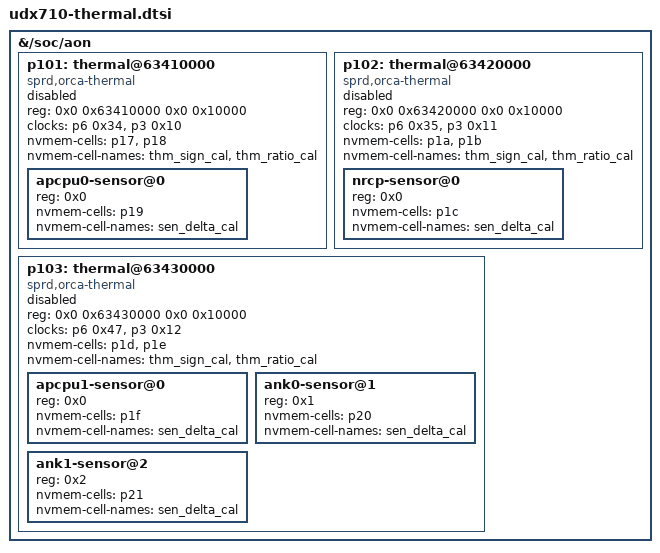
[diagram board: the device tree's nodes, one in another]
// SPDX-License-Identifier: GPL-2.0-only
/* UDX710 on-die thermal blocks and silicon calibration connections. */
&{/soc/aon} {
	p101: thermal@63410000 {
		compatible = "sprd,orca-thermal";
		reg = <0x0 0x63410000 0x0 0x10000>;
		clock-names = "enable", "functional";
		clocks = <&p6 0x34 &p3 0x10>;
		#thermal-sensor-cells = <0x1>;
		nvmem-cells = <&p17 &p18>;
		nvmem-cell-names = "thm_sign_cal", "thm_ratio_cal";
		phandle = <0x101>;
		#address-cells = <0x1>;
		#size-cells = <0x0>;
		status = "disabled";
		apcpu0-sensor@0 {
			reg = <0x0>;
			nvmem-cells = <&p19>;
			nvmem-cell-names = "sen_delta_cal";
		};
	};

	p102: thermal@63420000 {
		compatible = "sprd,orca-thermal";
		reg = <0x0 0x63420000 0x0 0x10000>;
		clock-names = "enable", "functional";
		clocks = <&p6 0x35 &p3 0x11>;
		#thermal-sensor-cells = <0x1>;
		nvmem-cells = <&p1a &p1b>;
		nvmem-cell-names = "thm_sign_cal", "thm_ratio_cal";
		phandle = <0x102>;
		#address-cells = <0x1>;
		#size-cells = <0x0>;
		status = "disabled";
		nrcp-sensor@0 {
			reg = <0x0>;
			nvmem-cells = <&p1c>;
			nvmem-cell-names = "sen_delta_cal";
		};
	};

	p103: thermal@63430000 {
		compatible = "sprd,orca-thermal";
		reg = <0x0 0x63430000 0x0 0x10000>;
		clock-names = "enable", "functional";
		clocks = <&p6 0x47 &p3 0x12>;
		#thermal-sensor-cells = <0x1>;
		nvmem-cells = <&p1d &p1e>;
		nvmem-cell-names = "thm_sign_cal", "thm_ratio_cal";
		phandle = <0x103>;
		#address-cells = <0x1>;
		#size-cells = <0x0>;
		status = "disabled";
		apcpu1-sensor@0 {
			reg = <0x0>;
			nvmem-cells = <&p1f>;
			nvmem-cell-names = "sen_delta_cal";
		};
		ank0-sensor@1 {
			reg = <0x1>;
			nvmem-cells = <&p20>;
			nvmem-cell-names = "sen_delta_cal";
		};
		ank1-sensor@2 {
			reg = <0x2>;
			nvmem-cells = <&p21>;
			nvmem-cell-names = "sen_delta_cal";
		};
	};
};
